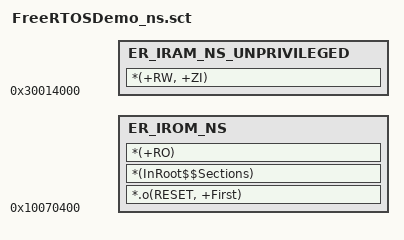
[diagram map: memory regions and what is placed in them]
LR_APP 0x10070400 ; load region
{
    ER_IROM_NS +0 ALIGN 32
    {
        *.o(RESET, +First)
        *(InRoot$$Sections) ; All sections that must be in a root region
        *(+RO)
    }

    ER_IRAM_NS_UNPRIVILEGED 0x30014000 ALIGN 32
    {
        *(+RW, +ZI)
    }

}
